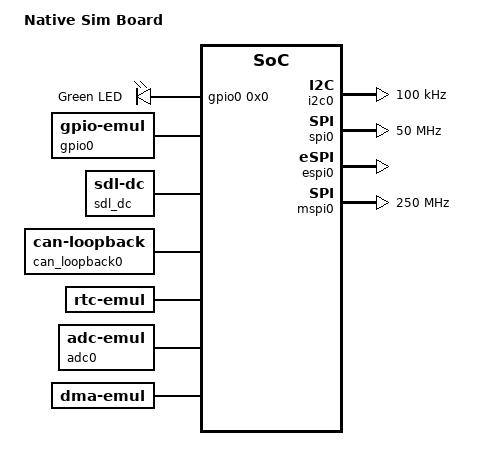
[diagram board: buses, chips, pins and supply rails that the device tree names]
/dts-v1/;

/* node '/' defined in zephyr/dts/common/skeleton.dtsi:9 */
/ {
	#address-cells = < 0x1 >;    /* in zephyr/dts/common/skeleton.dtsi:10 */
	#size-cells = < 0x1 >;       /* in zephyr/dts/common/skeleton.dtsi:11 */
	model = "Native Sim Board";  /* in zephyr/boards/native/native_sim/native_sim.dts:14 */
	compatible = "zephyr,posix"; /* in zephyr/boards/native/native_sim/native_sim.dts:15 */

	/* node '/chosen' defined in zephyr/dts/common/skeleton.dtsi:13 */
	chosen {
		zephyr,console = &uart0;                     /* in zephyr/boards/native/native_sim/native_sim.dts:18 */
		zephyr,shell-uart = &uart0;                  /* in zephyr/boards/native/native_sim/native_sim.dts:19 */
		zephyr,uart-mcumgr = &uart0;                 /* in zephyr/boards/native/native_sim/native_sim.dts:20 */
		zephyr,flash = &flash0;                      /* in zephyr/boards/native/native_sim/native_sim.dts:21 */
		zephyr,entropy = &rng;                       /* in zephyr/boards/native/native_sim/native_sim.dts:22 */
		zephyr,flash-controller = &flashcontroller0; /* in zephyr/boards/native/native_sim/native_sim.dts:23 */
		zephyr,display = &sdl_dc;                    /* in zephyr/boards/native/native_sim/native_sim.dts:24 */
		zephyr,canbus = &can_loopback0;              /* in zephyr/boards/native/native_sim/native_sim.dts:25 */
		zephyr,code-partition = &slot0_partition;    /* in zephyr/boards/native/native_sim/native_sim.dts:26 */
		zephyr,bt-hci = &bt_hci_userchan;            /* in zephyr/boards/native/native_sim/native_sim.dts:27 */
		zephyr,touch = &input_sdl_touch;             /* in zephyr/boards/native/native_sim/native_sim.dts:28 */
	};

	/* node '/aliases' defined in zephyr/dts/common/skeleton.dtsi:15 */
	aliases {
		eeprom-0 = &eeprom0;   /* in zephyr/boards/native/native_sim/native_sim.dts:32 */
		i2c-0 = &i2c0;         /* in zephyr/boards/native/native_sim/native_sim.dts:33 */
		spi-0 = &spi0;         /* in zephyr/boards/native/native_sim/native_sim.dts:34 */
		led0 = &led0;          /* in zephyr/boards/native/native_sim/native_sim.dts:35 */
		rtc = &rtc;            /* in zephyr/boards/native/native_sim/native_sim.dts:36 */
		rc = &sitl_rc0;        /* in cerebri/boards/native_sim.overlay:5 */
		imu0 = &sitl_imu0;     /* in cerebri/boards/native_sim.overlay:6 */
		motors = &sitl_dshot0; /* in cerebri/boards/native_sim.overlay:7 */
	};

	/* node '/leds' defined in zephyr/boards/native/native_sim/native_sim.dts:39 */
	leds {
		compatible = "gpio-leds"; /* in zephyr/boards/native/native_sim/native_sim.dts:40 */

		/* node '/leds/led_0' defined in zephyr/boards/native/native_sim/native_sim.dts:42 */
		led0: led_0 {
			gpios = < &gpio0 0x0 0x0 >; /* in zephyr/boards/native/native_sim/native_sim.dts:43 */
			label = "Green LED";        /* in zephyr/boards/native/native_sim/native_sim.dts:44 */
		};
	};

	/* node '/lvgl_pointer' defined in zephyr/boards/native/native_sim/native_sim.dts:48 */
	lvgl_pointer {
		compatible = "zephyr,lvgl-pointer-input"; /* in zephyr/boards/native/native_sim/native_sim.dts:49 */
		input = < &input_sdl_touch >;             /* in zephyr/boards/native/native_sim/native_sim.dts:50 */
	};

	/* node '/cpus' defined in zephyr/boards/native/native_sim/native_sim.dts:53 */
	cpus {
		#address-cells = < 0x1 >; /* in zephyr/boards/native/native_sim/native_sim.dts:54 */
		#size-cells = < 0x0 >;    /* in zephyr/boards/native/native_sim/native_sim.dts:55 */

		/* node '/cpus/cpu@0' defined in zephyr/boards/native/native_sim/native_sim.dts:57 */
		cpu0: cpu@0 {
			compatible = "zephyr,native-sim-cpu"; /* in zephyr/boards/native/native_sim/native_sim.dts:58 */
			reg = < 0x0 >;                        /* in zephyr/boards/native/native_sim/native_sim.dts:59 */
		};
	};

	/* node '/flash-controller@0' defined in zephyr/boards/native/native_sim/native_sim.dts:63 */
	flashcontroller0: flash-controller@0 {
		compatible = "zephyr,sim-flash"; /* in zephyr/boards/native/native_sim/native_sim.dts:64 */
		reg = < 0x0 0x200000 >;          /* in zephyr/boards/native/native_sim/native_sim.dts:65 */
		#address-cells = < 0x1 >;        /* in zephyr/boards/native/native_sim/native_sim.dts:67 */
		#size-cells = < 0x1 >;           /* in zephyr/boards/native/native_sim/native_sim.dts:68 */
		erase-value = < 0xff >;          /* in zephyr/boards/native/native_sim/native_sim.dts:69 */

		/* node '/flash-controller@0/flash@0' defined in zephyr/boards/native/native_sim/native_sim.dts:71 */
		flash0: flash@0 {
			status = "okay";               /* in zephyr/boards/native/native_sim/native_sim.dts:72 */
			compatible = "soc-nv-flash";   /* in zephyr/boards/native/native_sim/native_sim.dts:73 */
			erase-block-size = < 0x1000 >; /* in zephyr/boards/native/native_sim/native_sim.dts:74 */
			write-block-size = < 0x1 >;    /* in zephyr/boards/native/native_sim/native_sim.dts:75 */
			reg = < 0x0 0x200000 >;        /* in zephyr/boards/native/native_sim/native_sim.dts:76 */

			/* node '/flash-controller@0/flash@0/partitions' defined in zephyr/boards/native/native_sim/native_sim.dts:78 */
			partitions {
				compatible = "fixed-partitions"; /* in zephyr/boards/native/native_sim/native_sim.dts:79 */
				#address-cells = < 0x1 >;        /* in zephyr/boards/native/native_sim/native_sim.dts:80 */
				#size-cells = < 0x1 >;           /* in zephyr/boards/native/native_sim/native_sim.dts:81 */

				/* node '/flash-controller@0/flash@0/partitions/partition@0' defined in zephyr/boards/native/native_sim/native_sim.dts:83 */
				boot_partition: partition@0 {
					label = "mcuboot";    /* in zephyr/boards/native/native_sim/native_sim.dts:84 */
					reg = < 0x0 0xc000 >; /* in zephyr/boards/native/native_sim/native_sim.dts:85 */
				};

				/* node '/flash-controller@0/flash@0/partitions/partition@c000' defined in zephyr/boards/native/native_sim/native_sim.dts:88 */
				slot0_partition: partition@c000 {
					label = "image-0";        /* in zephyr/boards/native/native_sim/native_sim.dts:89 */
					reg = < 0xc000 0x69000 >; /* in zephyr/boards/native/native_sim/native_sim.dts:90 */
				};

				/* node '/flash-controller@0/flash@0/partitions/partition@75000' defined in zephyr/boards/native/native_sim/native_sim.dts:93 */
				slot1_partition: partition@75000 {
					label = "image-1";         /* in zephyr/boards/native/native_sim/native_sim.dts:94 */
					reg = < 0x75000 0x69000 >; /* in zephyr/boards/native/native_sim/native_sim.dts:95 */
				};

				/* node '/flash-controller@0/flash@0/partitions/partition@de000' defined in zephyr/boards/native/native_sim/native_sim.dts:98 */
				scratch_partition: partition@de000 {
					label = "image-scratch";   /* in zephyr/boards/native/native_sim/native_sim.dts:99 */
					reg = < 0xde000 0x1e000 >; /* in zephyr/boards/native/native_sim/native_sim.dts:100 */
				};

				/* node '/flash-controller@0/flash@0/partitions/partition@fc000' defined in zephyr/boards/native/native_sim/native_sim.dts:103 */
				storage_partition: partition@fc000 {
					label = "storage";        /* in zephyr/boards/native/native_sim/native_sim.dts:104 */
					reg = < 0xfc000 0x4000 >; /* in zephyr/boards/native/native_sim/native_sim.dts:105 */
				};
			};
		};
	};

	/* node '/eeprom' defined in zephyr/boards/native/native_sim/native_sim.dts:111 */
	eeprom0: eeprom {
		status = "okay";                  /* in zephyr/boards/native/native_sim/native_sim.dts:112 */
		compatible = "zephyr,sim-eeprom"; /* in zephyr/boards/native/native_sim/native_sim.dts:113 */
		size = < 0x8000 >;                /* in zephyr/boards/native/native_sim/native_sim.dts:114 */
	};

	/* node '/i2c@100' defined in zephyr/boards/native/native_sim/native_sim.dts:117 */
	i2c0: i2c@100 {
		status = "okay";                           /* in zephyr/boards/native/native_sim/native_sim.dts:118 */
		compatible = "zephyr,i2c-emul-controller"; /* in zephyr/boards/native/native_sim/native_sim.dts:119 */
		clock-frequency = < 0x186a0 >;             /* in zephyr/boards/native/native_sim/native_sim.dts:120 */
		#address-cells = < 0x1 >;                  /* in zephyr/boards/native/native_sim/native_sim.dts:121 */
		#size-cells = < 0x0 >;                     /* in zephyr/boards/native/native_sim/native_sim.dts:122 */
		#forward-cells = < 0x1 >;                  /* in zephyr/boards/native/native_sim/native_sim.dts:123 */
		reg = < 0x100 0x4 >;                       /* in zephyr/boards/native/native_sim/native_sim.dts:124 */
	};

	/* node '/spi@200' defined in zephyr/boards/native/native_sim/native_sim.dts:127 */
	spi0: spi@200 {
		status = "okay";                           /* in zephyr/boards/native/native_sim/native_sim.dts:128 */
		compatible = "zephyr,spi-emul-controller"; /* in zephyr/boards/native/native_sim/native_sim.dts:129 */
		clock-frequency = < 0x2faf080 >;           /* in zephyr/boards/native/native_sim/native_sim.dts:130 */
		#address-cells = < 0x1 >;                  /* in zephyr/boards/native/native_sim/native_sim.dts:131 */
		#size-cells = < 0x0 >;                     /* in zephyr/boards/native/native_sim/native_sim.dts:132 */
		reg = < 0x200 0x4 >;                       /* in zephyr/boards/native/native_sim/native_sim.dts:133 */
	};

	/* node '/espi@300' defined in zephyr/boards/native/native_sim/native_sim.dts:136 */
	espi0: espi@300 {
		status = "okay";                            /* in zephyr/boards/native/native_sim/native_sim.dts:137 */
		compatible = "zephyr,espi-emul-controller"; /* in zephyr/boards/native/native_sim/native_sim.dts:138 */
		reg = < 0x300 0x4 >;                        /* in zephyr/boards/native/native_sim/native_sim.dts:139 */
		#address-cells = < 0x1 >;                   /* in zephyr/boards/native/native_sim/native_sim.dts:140 */
		#size-cells = < 0x0 >;                      /* in zephyr/boards/native/native_sim/native_sim.dts:141 */
	};

	/* node '/mspi@400' defined in zephyr/boards/native/native_sim/native_sim.dts:144 */
	mspi0: mspi@400 {
		status = "okay";                            /* in zephyr/boards/native/native_sim/native_sim.dts:145 */
		compatible = "zephyr,mspi-emul-controller"; /* in zephyr/boards/native/native_sim/native_sim.dts:146 */
		clock-frequency = < 0xee6b280 >;            /* in zephyr/boards/native/native_sim/native_sim.dts:147 */
		reg = < 0x400 0x4 >;                        /* in zephyr/boards/native/native_sim/native_sim.dts:148 */
		#address-cells = < 0x1 >;                   /* in zephyr/boards/native/native_sim/native_sim.dts:149 */
		#size-cells = < 0x0 >;                      /* in zephyr/boards/native/native_sim/native_sim.dts:150 */
	};

	/* node '/uart' defined in zephyr/boards/native/native_sim/native_sim.dts:153 */
	uart0: uart {
		status = "okay";                       /* in zephyr/boards/native/native_sim/native_sim.dts:154 */
		compatible = "zephyr,native-pty-uart"; /* in zephyr/boards/native/native_sim/native_sim.dts:155 */
		current-speed = < 0x0 >;               /* in zephyr/boards/native/native_sim/native_sim.dts:159 */
	};

	/* node '/uart_1' defined in zephyr/boards/native/native_sim/native_sim.dts:162 */
	uart1: uart_1 {
		status = "disabled";                   /* in zephyr/boards/native/native_sim/native_sim.dts:163 */
		compatible = "zephyr,native-pty-uart"; /* in zephyr/boards/native/native_sim/native_sim.dts:164 */
		current-speed = < 0x0 >;               /* in zephyr/boards/native/native_sim/native_sim.dts:168 */
	};

	/* node '/rng' defined in zephyr/boards/native/native_sim/native_sim.dts:171 */
	rng: rng {
		status = "okay";                      /* in zephyr/boards/native/native_sim/native_sim.dts:172 */
		compatible = "zephyr,native-sim-rng"; /* in zephyr/boards/native/native_sim/native_sim.dts:173 */
	};

	/* node '/counter' defined in zephyr/boards/native/native_sim/native_sim.dts:176 */
	counter0: counter {
		status = "okay";                          /* in zephyr/boards/native/native_sim/native_sim.dts:177 */
		compatible = "zephyr,native-sim-counter"; /* in zephyr/boards/native/native_sim/native_sim.dts:178 */
	};

	/* node '/gpio_emul' defined in zephyr/boards/native/native_sim/native_sim.dts:181 */
	gpio0: gpio_emul {
		status = "okay";                 /* in zephyr/boards/native/native_sim/native_sim.dts:182 */
		compatible = "zephyr,gpio-emul"; /* in zephyr/boards/native/native_sim/native_sim.dts:183 */
		rising-edge;                     /* in zephyr/boards/native/native_sim/native_sim.dts:184 */
		falling-edge;                    /* in zephyr/boards/native/native_sim/native_sim.dts:185 */
		high-level;                      /* in zephyr/boards/native/native_sim/native_sim.dts:186 */
		low-level;                       /* in zephyr/boards/native/native_sim/native_sim.dts:187 */
		gpio-controller;                 /* in zephyr/boards/native/native_sim/native_sim.dts:188 */
		#gpio-cells = < 0x2 >;           /* in zephyr/boards/native/native_sim/native_sim.dts:189 */
		phandle = < 0x1 >;               /* in zephyr/boards/native/native_sim/native_sim.dts:43 */
	};

	/* node '/udc0' defined in zephyr/boards/native/native_sim/native_sim.dts:192 */
	zephyr_udc0: udc0 {
		compatible = "zephyr,native-posix-udc"; /* in zephyr/boards/native/native_sim/native_sim.dts:193 */
	};

	/* node '/sdl_dc' defined in zephyr/boards/native/native_sim/native_sim.dts:196 */
	sdl_dc: sdl_dc {
		compatible = "zephyr,sdl-dc"; /* in zephyr/boards/native/native_sim/native_sim.dts:197 */
		height = < 0xf0 >;            /* in zephyr/boards/native/native_sim/native_sim.dts:198 */
		width = < 0x140 >;            /* in zephyr/boards/native/native_sim/native_sim.dts:199 */
		phandle = < 0x3 >;            /* in zephyr/boards/native/native_sim/native_sim.dts:204 */
	};

	/* node '/input-sdl-touch' defined in zephyr/boards/native/native_sim/native_sim.dts:202 */
	input_sdl_touch: input-sdl-touch {
		compatible = "zephyr,input-sdl-touch"; /* in zephyr/boards/native/native_sim/native_sim.dts:203 */
		display = < &sdl_dc >;                 /* in zephyr/boards/native/native_sim/native_sim.dts:204 */
		phandle = < 0x2 >;                     /* in zephyr/boards/native/native_sim/native_sim.dts:50 */
	};

	/* node '/can_loopback0' defined in zephyr/boards/native/native_sim/native_sim.dts:207 */
	can_loopback0: can_loopback0 {
		status = "okay";                    /* in zephyr/boards/native/native_sim/native_sim.dts:208 */
		compatible = "zephyr,can-loopback"; /* in zephyr/boards/native/native_sim/native_sim.dts:209 */
	};

	/* node '/can' defined in zephyr/boards/native/native_sim/native_sim.dts:212 */
	can0: can {
		status = "disabled";                    /* in zephyr/boards/native/native_sim/native_sim.dts:213 */
		compatible = "zephyr,native-linux-can"; /* in zephyr/boards/native/native_sim/native_sim.dts:214 */
		host-interface = "zcan0";               /* in zephyr/boards/native/native_sim/native_sim.dts:218 */
	};

	/* node '/rtc' defined in zephyr/boards/native/native_sim/native_sim.dts:221 */
	rtc: rtc {
		status = "okay";                /* in zephyr/boards/native/native_sim/native_sim.dts:222 */
		compatible = "zephyr,rtc-emul"; /* in zephyr/boards/native/native_sim/native_sim.dts:223 */
		alarms-count = < 0x2 >;         /* in zephyr/boards/native/native_sim/native_sim.dts:224 */
	};

	/* node '/adc' defined in zephyr/boards/native/native_sim/native_sim.dts:227 */
	adc0: adc {
		compatible = "zephyr,adc-emul"; /* in zephyr/boards/native/native_sim/native_sim.dts:228 */
		nchannels = < 0x2 >;            /* in zephyr/boards/native/native_sim/native_sim.dts:229 */
		#io-channel-cells = < 0x1 >;    /* in zephyr/boards/native/native_sim/native_sim.dts:230 */
		status = "okay";                /* in zephyr/boards/native/native_sim/native_sim.dts:231 */
	};

	/* node '/dma' defined in zephyr/boards/native/native_sim/native_sim.dts:234 */
	dma: dma {
		compatible = "zephyr,dma-emul"; /* in zephyr/boards/native/native_sim/native_sim.dts:235 */
		#dma-cells = < 0x1 >;           /* in zephyr/boards/native/native_sim/native_sim.dts:236 */
		stack-size = < 0x1000 >;        /* in zephyr/boards/native/native_sim/native_sim.dts:237 */
	};

	/* node '/bt_hci_userchan' defined in zephyr/boards/native/native_sim/native_sim.dts:240 */
	bt_hci_userchan: bt_hci_userchan {
		compatible = "zephyr,bt-hci-userchan"; /* in zephyr/boards/native/native_sim/native_sim.dts:241 */
		status = "okay";                       /* in zephyr/boards/native/native_sim/native_sim.dts:242 */
	};

	/* node '/performance-states' defined in zephyr/boards/native/native_sim/native_sim.dts:245 */
	performance-states {

		/* node '/performance-states/pstate_0' defined in zephyr/boards/native/native_sim/native_sim.dts:246 */
		pstate_0: pstate_0 {
			compatible = "zephyr,native-sim-pstate"; /* in zephyr/boards/native/native_sim/native_sim.dts:247 */
			load-threshold = < 0x32 >;               /* in zephyr/boards/native/native_sim/native_sim.dts:248 */
			pstate-id = < 0x0 >;                     /* in zephyr/boards/native/native_sim/native_sim.dts:249 */
		};

		/* node '/performance-states/pstate_1' defined in zephyr/boards/native/native_sim/native_sim.dts:252 */
		pstate_1: pstate_1 {
			compatible = "zephyr,native-sim-pstate"; /* in zephyr/boards/native/native_sim/native_sim.dts:253 */
			load-threshold = < 0x14 >;               /* in zephyr/boards/native/native_sim/native_sim.dts:254 */
			pstate-id = < 0x1 >;                     /* in zephyr/boards/native/native_sim/native_sim.dts:255 */
		};

		/* node '/performance-states/pstate_2' defined in zephyr/boards/native/native_sim/native_sim.dts:258 */
		pstate_2: pstate_2 {
			compatible = "zephyr,native-sim-pstate"; /* in zephyr/boards/native/native_sim/native_sim.dts:259 */
			load-threshold = < 0x0 >;                /* in zephyr/boards/native/native_sim/native_sim.dts:260 */
			pstate-id = < 0x2 >;                     /* in zephyr/boards/native/native_sim/native_sim.dts:261 */
		};
	};

	/* node '/sitl_udp' defined in cerebri/boards/native_sim.overlay:10 */
	sitl_udp0: sitl_udp {
		compatible = "cognipilot,sitl-udp"; /* in cerebri/boards/native_sim.overlay:11 */
		status = "okay";                    /* in cerebri/boards/native_sim.overlay:12 */
	};

	/* node '/sitl_rc' defined in cerebri/boards/native_sim.overlay:15 */
	sitl_rc0: sitl_rc {
		compatible = "cognipilot,sitl-rc"; /* in cerebri/boards/native_sim.overlay:16 */
		status = "okay";                   /* in cerebri/boards/native_sim.overlay:17 */
	};

	/* node '/sitl_imu' defined in cerebri/boards/native_sim.overlay:20 */
	sitl_imu0: sitl_imu {
		compatible = "cognipilot,sitl-imu"; /* in cerebri/boards/native_sim.overlay:21 */
		status = "okay";                    /* in cerebri/boards/native_sim.overlay:22 */
	};

	/* node '/sitl_dshot' defined in cerebri/boards/native_sim.overlay:25 */
	sitl_dshot0: sitl_dshot {
		compatible = "cognipilot,sitl-dshot"; /* in cerebri/boards/native_sim.overlay:26 */
		status = "okay";                      /* in cerebri/boards/native_sim.overlay:27 */
		channel-count = < 0x4 >;              /* in cerebri/boards/native_sim.overlay:28 */
	};
};
